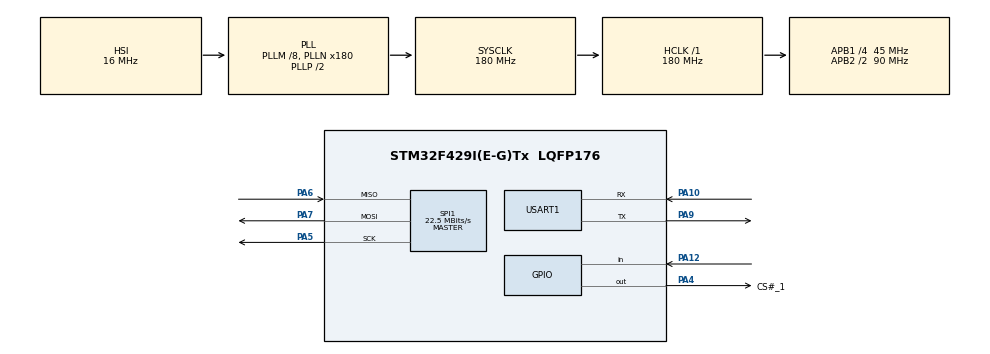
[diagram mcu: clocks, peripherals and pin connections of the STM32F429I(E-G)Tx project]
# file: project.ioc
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Mcu.Family=STM32F4
Mcu.Name=STM32F429I(E-G)Tx
Mcu.Package=LQFP176
NVIC.PriorityGroup=NVIC_PRIORITYGROUP_4
NVIC.TIM7_IRQn=true\:0\:0\:false\:false\:true\:false\:true
NVIC.TimeBase=TIM7_IRQn
NVIC.TimeBaseIP=TIM7
PA10.Mode=Asynchronous
PA10.Signal=USART1_RX
PA12.Signal=GPIO_Input
PA13.Mode=Serial_Wire
PA13.Signal=SYS_JTMS-SWDIO
PA14.Mode=Serial_Wire
PA14.Signal=SYS_JTCK-SWCLK
PA4.GPIO_Label=CS\#_1
PA4.Signal=GPIO_Output
PA5.Mode=Full_Duplex_Master
PA5.Signal=SPI1_SCK
PA6.Mode=Full_Duplex_Master
PA6.Signal=SPI1_MISO
PA7.Mode=Full_Duplex_Master
PA7.Signal=SPI1_MOSI
PA9.Mode=Asynchronous
PA9.Signal=USART1_TX
PC14/OSC32_IN.Mode=LSE-External-Oscillator
PC14/OSC32_IN.Signal=RCC_OSC32_IN
PC15/OSC32_OUT.Mode=LSE-External-Oscillator
PC15/OSC32_OUT.Signal=RCC_OSC32_OUT
PH0/OSC_IN.Mode=HSE-External-Oscillator
PH0/OSC_IN.Signal=RCC_OSC_IN
PH1/OSC_OUT.Mode=HSE-External-Oscillator
PH1/OSC_OUT.Signal=RCC_OSC_OUT
ProjectManager.HeapSize=0x80
ProjectManager.StackSize=0x800
ProjectManager.TargetToolchain=MDK-ARM V5.27
RCC.48MHZClocksFreq_Value=90000000
RCC.AHBFreq_Value=180000000
RCC.APB1CLKDivider=RCC_HCLK_DIV4
RCC.APB1Freq_Value=45000000
RCC.APB1TimFreq_Value=90000000
RCC.APB2CLKDivider=RCC_HCLK_DIV2
RCC.APB2Freq_Value=90000000
RCC.APB2TimFreq_Value=180000000
RCC.CortexFreq_Value=180000000
RCC.HCLKFreq_Value=180000000
RCC.HSE_VALUE=25000000
RCC.HSI_VALUE=16000000
RCC.PLLM=8
RCC.PLLN=180
RCC.SYSCLKFreq_VALUE=180000000
RCC.SYSCLKSource=RCC_SYSCLKSOURCE_PLLCLK
RCC.VCOOutputFreq_Value=360000000
SPI1.BaudRatePrescaler=SPI_BAUDRATEPRESCALER_4
SPI1.CLKPhase=SPI_PHASE_1EDGE
SPI1.CLKPolarity=SPI_POLARITY_LOW
SPI1.CalculateBaudRate=22.5 MBits/s
SPI1.Direction=SPI_DIRECTION_2LINES
SPI1.Mode=SPI_MODE_MASTER
SPI1.VirtualType=VM_MASTER
USART1.VirtualMode=VM_ASYNC
VP_SYS_VS_tim7.Mode=TIM7
board=custom

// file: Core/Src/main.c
/* USER CODE BEGIN Header */
/**
  ******************************************************************************
  * @file           : main.c
  * @brief          : Main program body
  ******************************************************************************
  * @attention
  *
  * <h2><center>&copy; Copyright (c) 2021 STMicroelectronics.
  * All rights reserved.</center></h2>
  *
  * This software component is licensed by ST under BSD 3-Clause license,
  * the "License"; You may not use this file except in compliance with the
  * License. You may obtain a copy of the License at:
  *                        opensource.org/licenses/BSD-3-Clause
  *
  ******************************************************************************
  */
#define  _PRINTF_OPEN
/* USER CODE END Header */
#include "main.h"
#include "spi.h"
#include "usart.h"
#include "gpio.h"

/* USER CODE BEGIN Includes */
#include "../../user_bsp/ch395/ch395cmd.h"
/* USER CODE END Includes */

/* USER CODE BEGIN PV */
extern SOCKET_HandleTypedef  Socket_0;
extern CH395_HandleTypedef  ch395_0;
/* USER CODE END PV */

void SystemClock_Config(void);
/* USER CODE BEGIN PFP */
extern void MB_Parse_Data(void);
/* USER CODE END PFP */

int main(void)
{

  /* MCU Configuration--------------------------------------------------------*/

  /* Reset of all peripherals, Initializes the Flash interface and the Systick. */
  HAL_Init();

  /* Configure the system clock */
  SystemClock_Config();

  /* Initialize all configured peripherals */
  MX_GPIO_Init();
  MX_USART1_UART_Init();
  MX_SPI1_Init();
  /* USER CODE BEGIN 2 */
    //------------------------------------//
    //初始化395芯片
    CH395_Init(&ch395_0,&Socket_0);
    //------------------------------------//

    //查询CH395PHY未连接
    while(CH395CMDGetPHYStatus(&ch395_0) == PHY_DISCONN)
    {
        HAL_Delay(200);
    }

    //------------------------------------//
    //初始化socket
    CH395_InitSocketParam(&ch395_0,&Socket_0);
    //------------------------------------//
  /* USER CODE END 2 */

  /* Infinite loop */
    while (1)
    {

    /* USER CODE BEGIN 3 */
        if(HAL_GPIO_ReadPin(ch395_0.INT_PORT,ch395_0.INT_PIN) == 0)
        {
            CH395_SocketIRQ(&ch395_0,&Socket_0);
        }
    }
  /* USER CODE END 3 */
}

void SystemClock_Config(void)
{
  RCC_OscInitTypeDef RCC_OscInitStruct = {0};
  RCC_ClkInitTypeDef RCC_ClkInitStruct = {0};

  /** Configure the main internal regulator output voltage
  */
  __HAL_RCC_PWR_CLK_ENABLE();
  __HAL_PWR_VOLTAGESCALING_CONFIG(PWR_REGULATOR_VOLTAGE_SCALE1);
  /** Initializes the RCC Oscillators according to the specified parameters
  * in the RCC_OscInitTypeDef structure.
  */
  RCC_OscInitStruct.OscillatorType = RCC_OSCILLATORTYPE_HSI;
  RCC_OscInitStruct.HSIState = RCC_HSI_ON;
  RCC_OscInitStruct.HSICalibrationValue = RCC_HSICALIBRATION_DEFAULT;
  RCC_OscInitStruct.PLL.PLLState = RCC_PLL_ON;
  RCC_OscInitStruct.PLL.PLLSource = RCC_PLLSOURCE_HSI;
  RCC_OscInitStruct.PLL.PLLM = 8;
  RCC_OscInitStruct.PLL.PLLN = 180;
  RCC_OscInitStruct.PLL.PLLP = RCC_PLLP_DIV2;
  RCC_OscInitStruct.PLL.PLLQ = 4;
  if (HAL_RCC_OscConfig(&RCC_OscInitStruct) != HAL_OK)
  {
    Error_Handler();
  }
  /** Activate the Over-Drive mode
  */
  if (HAL_PWREx_EnableOverDrive() != HAL_OK)
  {
    Error_Handler();
  }
  /** Initializes the CPU, AHB and APB buses clocks
  */
  RCC_ClkInitStruct.ClockType = RCC_CLOCKTYPE_HCLK|RCC_CLOCKTYPE_SYSCLK
                              |RCC_CLOCKTYPE_PCLK1|RCC_CLOCKTYPE_PCLK2;
  RCC_ClkInitStruct.SYSCLKSource = RCC_SYSCLKSOURCE_PLLCLK;
  RCC_ClkInitStruct.AHBCLKDivider = RCC_SYSCLK_DIV1;
  RCC_ClkInitStruct.APB1CLKDivider = RCC_HCLK_DIV4;
  RCC_ClkInitStruct.APB2CLKDivider = RCC_HCLK_DIV2;

  if (HAL_RCC_ClockConfig(&RCC_ClkInitStruct, FLASH_LATENCY_5) != HAL_OK)
  {
    Error_Handler();
  }
}

/* USER CODE BEGIN 4 */
//按键中断回调
void HAL_GPIO_EXTI_Callback(uint16_t GPIO_Pin)
{

}
/* USER CODE END 4 */

 /**
  * @brief  Period elapsed callback in non blocking mode
  * @note   This function is called  when TIM7 interrupt took place, inside
  * HAL_TIM_IRQHandler(). It makes a direct call to HAL_IncTick() to increment
  * a global variable "uwTick" used as application time base.
  * @param  htim : TIM handle
  * @retval None
  */
void HAL_TIM_PeriodElapsedCallback(TIM_HandleTypeDef *htim)
{
  if (htim->Instance == TIM7) {
    HAL_IncTick();
  }
}

void Error_Handler(void)
{
    __disable_irq();
    while (1)
    {
    }
}

/************************ (C) COPYRIGHT STMicroelectronics *****END OF FILE****/
